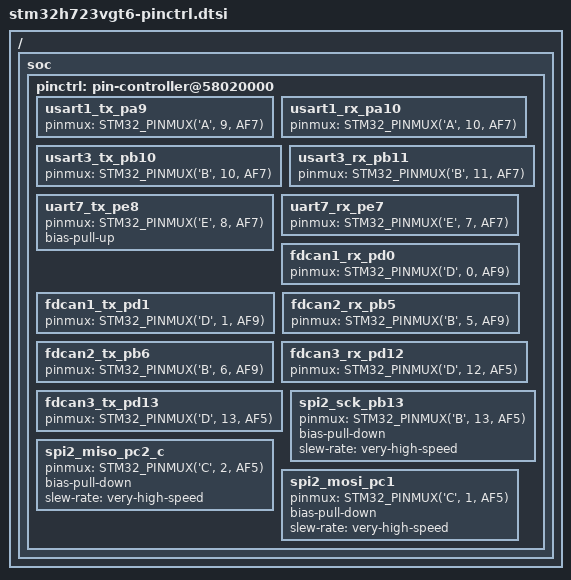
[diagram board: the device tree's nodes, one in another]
/*
 * SPDX-License-Identifier: Apache-2.0
 *
 * Custom pinctrl for STM32H723VGT6 (100-pin LQFP).
 *
 * This file contains only pin configurations that have been verified
 * on the DM_MC02 hardware — not an exhaustive list of all possible
 * STM32H723VGT6 pin functions.
 */

#include <dt-bindings/pinctrl/stm32-pinctrl.h>

/ {
	soc {
		pinctrl: pin-controller@58020000 {

			/* USART1 */
			usart1_tx_pa9: usart1_tx_pa9 {
				pinmux = <STM32_PINMUX('A', 9, AF7)>;
			};
			usart1_rx_pa10: usart1_rx_pa10 {
				pinmux = <STM32_PINMUX('A', 10, AF7)>;
			};

			/* USART3 */
			usart3_tx_pb10: usart3_tx_pb10 {
				pinmux = <STM32_PINMUX('B', 10, AF7)>;
			};
			usart3_rx_pb11: usart3_rx_pb11 {
				pinmux = <STM32_PINMUX('B', 11, AF7)>;
			};
			
			/* UART7 */
			uart7_tx_pe8: uart7_tx_pe8 {
				pinmux = <STM32_PINMUX('E', 8, AF7)>;
				bias-pull-up;
			};
			uart7_rx_pe7: uart7_rx_pe7 {
				pinmux = <STM32_PINMUX('E', 7, AF7)>;
			};

			/* FDCAN1 */
			fdcan1_rx_pd0: fdcan1_rx_pd0 {
				pinmux = <STM32_PINMUX('D', 0, AF9)>;
			};
			fdcan1_tx_pd1: fdcan1_tx_pd1 {
				pinmux = <STM32_PINMUX('D', 1, AF9)>;
			};

			/* FDCAN2 */
			fdcan2_rx_pb5: fdcan2_rx_pb5 {
				pinmux = <STM32_PINMUX('B', 5, AF9)>;
			};

			fdcan2_tx_pb6: fdcan2_tx_pb6 {
				pinmux = <STM32_PINMUX('B', 6, AF9)>;
			};
			
			/* FDCAN3 */
			fdcan3_rx_pd12: fdcan3_rx_pd12 {
				pinmux = <STM32_PINMUX('D', 12, AF5)>;
			};
			fdcan3_tx_pd13: fdcan3_tx_pd13 {
				pinmux = <STM32_PINMUX('D', 13, AF5)>;
			};

			/* SPI2 */
			spi2_sck_pb13: spi2_sck_pb13 {
				pinmux = <STM32_PINMUX('B', 13, AF5)>;
				bias-pull-down;
				slew-rate = "very-high-speed";
			};
			spi2_miso_pc2_c: spi2_miso_pc2_c {
				pinmux = <STM32_PINMUX('C', 2, AF5)>;
				bias-pull-down;
				slew-rate = "very-high-speed";
			};
			spi2_mosi_pc1: spi2_mosi_pc1 {
				pinmux = <STM32_PINMUX('C', 1, AF5)>;
				bias-pull-down;
				slew-rate = "very-high-speed";
			};

		};
	};
};
